VERSION ""
NS_ :

BS_:

BU_: DIM BMS DCM GSM FSM PDM DEBUG

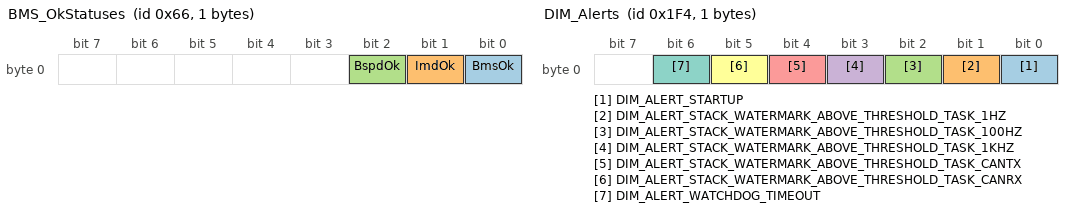
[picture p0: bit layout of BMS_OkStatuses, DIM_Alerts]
BO_ 102 BMS_OkStatuses: 1 BMS
SG_ BmsOk : 0|1@1+ (1,0) [0|1] "" DEBUG,DIM
SG_ ImdOk : 1|1@1+ (1,0) [0|1] "" DEBUG,DIM
SG_ BspdOk : 2|1@1+ (1,0) [0|1] "" DEBUG,DIM

BO_ 100 BMS_Alerts: 1 BMS
SG_ BMS_ALERT_DUMMY : 0|1@1+ (1,0) [0|1] "" DEBUG

BO_ 202 DCM_Test1: 1 DCM
SG_ Ex1 : 0|1@1+ (1,0) [0|1] "" DEBUG

BO_ 200 DCM_Alerts: 1 DCM
SG_ DCM_ALERT_DUMMY : 0|1@1+ (1,0) [0|1] "" DEBUG

BO_ 502 DIM_Vitals: 1 DIM
SG_ Heartbeat : 0|1@1+ (1,0) [0|1] "" DEBUG
SG_ State : 1|1@1+ (1,0) [0|0] "" DEBUG

BO_ 503 DIM_Switches: 1 DIM
SG_ StartSwitch : 0|1@1+ (1,0) [0|1] "" DEBUG
SG_ AuxSwitch : 1|1@1+ (1,0) [0|1] "" DEBUG

BO_ 504 DIM_Errors: 2 DIM
SG_ TxOverflowCount : 0|8@1+ (1,0) [0|255] "" DEBUG
SG_ RxOverflowCount : 8|8@1+ (1,0) [0|255] "" DEBUG

BO_ 504 DIMVitals: 1 DIM
SG_ Heartbeat : 0|1@1+ (1,0) [0|1] "" DEBUG,BMS

BO_ 500 DIM_AlertSet: 0 DIM
SG_ DIM_AlertSet : 0|0@1+ (1,0) [0|0] "" DEBUG

BO_ 500 DIM_Alerts: 1 DIM
SG_ DIM_ALERT_STARTUP : 0|1@1+ (1,0) [0|1] "" DEBUG
SG_ DIM_ALERT_STACK_WATERMARK_ABOVE_THRESHOLD_TASK_1HZ : 1|1@1+ (1,0) [0|1] "" DEBUG
SG_ DIM_ALERT_STACK_WATERMARK_ABOVE_THRESHOLD_TASK_100HZ : 2|1@1+ (1,0) [0|1] "" DEBUG
SG_ DIM_ALERT_STACK_WATERMARK_ABOVE_THRESHOLD_TASK_1KHZ : 3|1@1+ (1,0) [0|1] "" DEBUG
SG_ DIM_ALERT_STACK_WATERMARK_ABOVE_THRESHOLD_TASK_CANTX : 4|1@1+ (1,0) [0|1] "" DEBUG
SG_ DIM_ALERT_STACK_WATERMARK_ABOVE_THRESHOLD_TASK_CANRX : 5|1@1+ (1,0) [0|1] "" DEBUG
SG_ DIM_ALERT_WATCHDOG_TIMEOUT : 6|1@1+ (1,0) [0|1] "" DEBUG

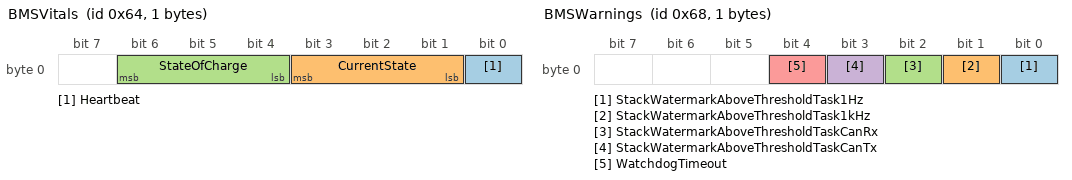
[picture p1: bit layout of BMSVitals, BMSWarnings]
BO_ 100 BMSVitals: 1 BMS
SG_ Heartbeat : 0|1@1+ (1,0) [0|1] "" DEBUG
SG_ CurrentState : 1|3@1+ (1,0) [0|4] "" DEBUG
SG_ StateOfCharge : 4|3@1+ (14.285714285714286,0) [0|100] "" DEBUG

BO_ 101 BMSCanFifoOverflow: 8 BMS
SG_ TxOverflowCount : 0|32@1+ (1,0) [0|4294967295] "" DEBUG
SG_ RxOverflowCount : 32|32@1+ (1,0) [0|4294967295] "" DEBUG

BO_ 103 BMSWatchdogTimeout: 1 BMS
SG_ TaskName : 0|3@1+ (1,0) [0|4] "" DEBUG

BO_ 104 BMSWarnings: 1 BMS
SG_ StackWatermarkAboveThresholdTask1Hz : 0|1@1+ (1,0) [0|1] "" DEBUG
SG_ StackWatermarkAboveThresholdTask1kHz : 1|1@1+ (1,0) [0|1] "" DEBUG
SG_ StackWatermarkAboveThresholdTaskCanRx : 2|1@1+ (1,0) [0|1] "" DEBUG
SG_ StackWatermarkAboveThresholdTaskCanTx : 3|1@1+ (1,0) [0|1] "" DEBUG
SG_ WatchdogTimeout : 4|1@1+ (1,0) [0|1] "" DEBUG

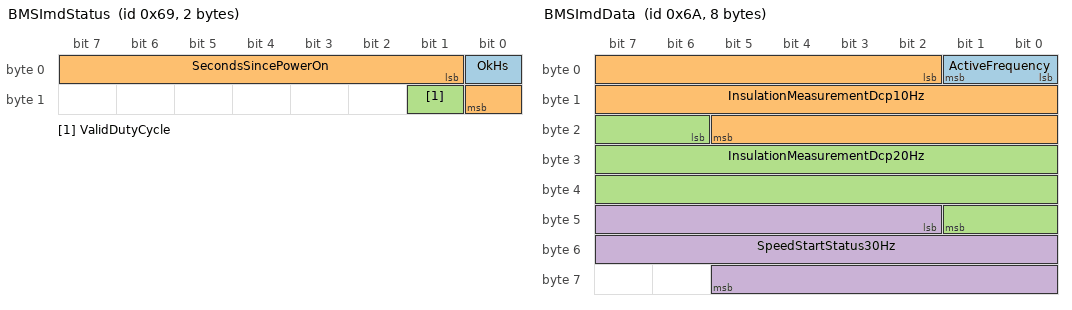
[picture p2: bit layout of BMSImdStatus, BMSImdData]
BO_ 105 BMSImdStatus: 2 BMS
SG_ OkHs : 0|1@1+ (1,0) [0|1] "" DEBUG
SG_ SecondsSincePowerOn : 1|8@1+ (1.0,0) [0|255] "Seconds" DEBUG
SG_ ValidDutyCycle : 9|1@1+ (1,0) [0|1] "" DEBUG

BO_ 106 BMSImdData: 8 BMS
SG_ ActiveFrequency : 0|2@1+ (6.666666666666667,0) [0|20] "Hz" DEBUG
SG_ InsulationMeasurementDcp10Hz : 2|20@1+ (0.1,0) [0|65535] "kOhm" DEBUG
SG_ InsulationMeasurementDcp20Hz : 22|20@1+ (0.1,0) [0|65535] "kOhm" DEBUG
SG_ SpeedStartStatus30Hz : 42|20@1+ (0.1,0) [0|65535] "" DEBUG

BO_ 107 BMSImdPwmOutput: 1 BMS
SG_ DutyCycle : 0|3@1+ (14.285714285714286,0) [0|100] "%" DEBUG
SG_ Frequency : 3|4@1+ (6.666666666666667,0) [0|100] "Hz" DEBUG

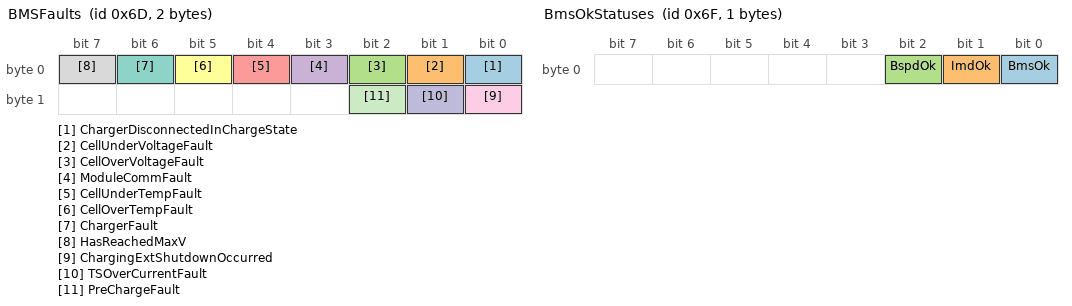
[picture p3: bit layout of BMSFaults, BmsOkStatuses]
BO_ 109 BMSFaults: 2 BMS
SG_ ChargerDisconnectedInChargeState : 0|1@1+ (1,0) [0|1] "" DEBUG
SG_ CellUnderVoltageFault : 1|1@1+ (1,0) [0|1] "" DEBUG
SG_ CellOverVoltageFault : 2|1@1+ (1,0) [0|1] "" DEBUG
SG_ ModuleCommFault : 3|1@1+ (1,0) [0|1] "" DEBUG
SG_ CellUnderTempFault : 4|1@1+ (1,0) [0|1] "" DEBUG
SG_ CellOverTempFault : 5|1@1+ (1,0) [0|1] "" DEBUG
SG_ ChargerFault : 6|1@1+ (1,0) [0|1] "" DEBUG
SG_ HasReachedMaxV : 7|1@1+ (1,0) [0|1] "" DEBUG
SG_ ChargingExtShutdownOccurred : 8|1@1+ (1,0) [0|1] "" DEBUG
SG_ TSOverCurrentFault : 9|1@1+ (1,0) [0|1] "" DEBUG
SG_ PreChargeFault : 10|1@1+ (1,0) [0|1] "" DEBUG

BO_ 110 BMSCharger: 1 BMS
SG_ IsConnected : 0|1@1+ (1,0) [0|1] "" DEBUG
SG_ IsChargingComplete : 1|1@1+ (1,0) [0|1] "" DEBUG

BO_ 111 BmsOkStatuses: 1 BMS
SG_ BmsOk : 0|1@1+ (1,0) [0|1] "" DEBUG
SG_ ImdOk : 1|1@1+ (1,0) [0|1] "" DEBUG
SG_ BspdOk : 2|1@1+ (1,0) [0|1] "" DEBUG

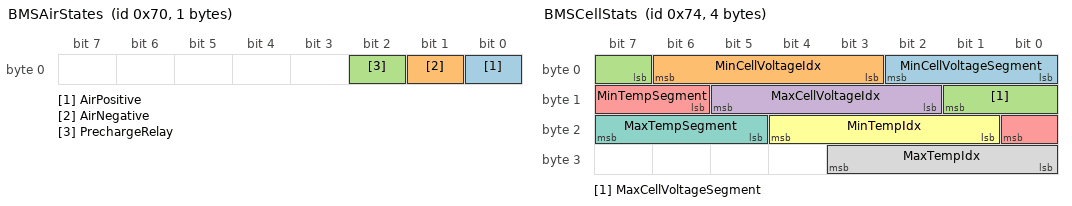
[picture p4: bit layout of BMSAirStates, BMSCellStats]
BO_ 112 BMSAirStates: 1 BMS
SG_ AirPositive : 0|1@1+ (1,0) [0|1] "" DEBUG
SG_ AirNegative : 1|1@1+ (1,0) [0|1] "" DEBUG
SG_ PrechargeRelay : 2|1@1+ (1,0) [0|1] "" DEBUG

BO_ 113 BMSMotorShutdownErrors: 1 BMS
SG_ BmsDummyMotorShutdown : 0|1@1+ (1,0) [0|1] "" DEBUG

BO_ 114 BMSCellTemperatures: 3 BMS
SG_ MinCellTemperature : 0|10@1+ (0.1,0) [0|100] "degC" DEBUG
SG_ MaxCellTemperature : 10|10@1+ (0.1,0) [0|100] "degC" DEBUG

BO_ 115 BMSCellVoltages: 4 BMS
SG_ MinCellVoltage : 0|16@1+ (0.0001,0) [0|5] "V" DEBUG
SG_ MaxCellVoltage : 16|16@1+ (0.0001,0) [0|5] "V" DEBUG

BO_ 116 BMSCellStats: 4 BMS
SG_ MinCellVoltageSegment : 0|3@1+ (1,0) [0|7] "" DEBUG
SG_ MinCellVoltageIdx : 3|4@1+ (1,0) [0|15] "" DEBUG
SG_ MaxCellVoltageSegment : 7|3@1+ (1.0,0) [0|7] "" DEBUG
SG_ MaxCellVoltageIdx : 10|4@1+ (1,0) [0|15] "" DEBUG
SG_ MinTempSegment : 14|3@1+ (1,0) [0|7] "" DEBUG
SG_ MinTempIdx : 17|4@1+ (1,0) [0|15] "" DEBUG
SG_ MaxTempSegment : 21|3@1+ (1,0) [0|7] "" DEBUG
SG_ MaxTempIdx : 24|4@1+ (1,0) [0|15] "" DEBUG

BO_ 117 BMSTractiveSystem: 5 BMS
SG_ TsVoltage : 0|23@1+ (0.0001,0) [0|600] "V" DEBUG
SG_ TsCurrent : 23|13@1+ (0.1,-300) [-300|300] "A" DEBUG

BO_ 118 BMSPackVoltage: 3 BMS
SG_ PackVoltage : 0|23@1+ (0.0001,0) [0|600] "V" DEBUG

BO_ 120 BMSAvailablePower: 3 BMS
SG_ AvailablePower : 0|20@1+ (0.1,0) [0|100000] "W" DEBUG

BO_ 150 BMS_AlertSet: 0 BMS
SG_ BMS_AlertSet : 0|0@1+ (1,0) [0|0] "" DEBUG

BO_ 151 BMS_AlertCleared: 0 BMS
SG_ BMS_AlertCleared : 0|0@1+ (1,0) [0|0] "" DEBUG

BO_ 202 DCM_Test1: 1 DCM
SG_ Ex1 : 0|1@1+ (1,0) [0|1] "" DEBUG

BO_ 203 DCMVitals: 1 DCM
SG_ Heartbeat : 0|1@1+ (1,0) [0|1] "" DEBUG,BMS

BO_ 200 DCM_AlertSet: 0 DCM
SG_ DCM_AlertSet : 0|0@1+ (1,0) [0|0] "" DEBUG

BO_ 201 DCM_AlertCleared: 0 DCM
SG_ DCM_AlertCleared : 0|0@1+ (1,0) [0|0] "" DEBUG

BO_ 603 GSM_Test1: 1 GSM
SG_ Ex1 : 0|1@1+ (1,0) [0|1] "" DEBUG

BO_ 600 GSM_Alerts: 1 GSM
SG_ GSM_ALERT_DUMMY : 0|1@1+ (1,0) [0|1] "" DEBUG

BO_ 303 FSM_Test1: 1 FSM
SG_ Ex1 : 0|1@1+ (1,0) [0|1] "" DEBUG

BO_ 304 FSMVitals: 1 FSM
SG_ Heartbeat : 0|1@1+ (1,0) [0|1] "" DEBUG,BMS

BO_ 300 FSM_AlertSet: 0 FSM
SG_ FSM_AlertSet : 0|0@1+ (1,0) [0|0] "" DEBUG

BO_ 301 FSM_AlertCleared: 0 FSM
SG_ FSM_AlertCleared : 0|0@1+ (1,0) [0|0] "" DEBUG

BO_ 403 PDM_Test1: 1 PDM
SG_ Ex1 : 0|1@1+ (1,0) [0|1] "" DEBUG

BO_ 404 PDMVitals: 1 PDM
SG_ Heartbeat : 0|1@1+ (1,0) [0|1] "" DEBUG,BMS

BO_ 400 PDM_AlertSet: 0 PDM
SG_ PDM_AlertSet : 0|0@1+ (1,0) [0|0] "" DEBUG

BO_ 401 PDM_AlertCleared: 0 PDM
SG_ PDM_AlertCleared : 0|0@1+ (1,0) [0|0] "" DEBUG

BA_DEF_  "BusType" STRING ;
BA_DEF_DEF_  "BusType" "CAN";

BA_ "GenSigStartValue" SG_ 502 Ex1 0;
BA_ "GenSigStartValue" SG_ 502 Ex2 0;
BA_ "GenSigStartValue" SG_ 503 Ex3 0;
BA_ "GenSigStartValue" SG_ 503 Ex4 0;
BA_ "GenSigStartValue" SG_ 503 Ex5 -120;
BA_ "GenSigStartValue" SG_ 504 Heartbeat 0;
BA_ "GenSigStartValue" SG_ 500 DIM_AlertSet 0;
BA_ "GenSigStartValue" SG_ 501 DIM_AlertCleared 0;
BA_ "GenSigStartValue" SG_ 100 Heartbeat 0;
BA_ "GenSigStartValue" SG_ 100 CurrentState 0;
BA_ "GenSigStartValue" SG_ 100 StateOfCharge 0;
BA_ "GenSigStartValue" SG_ 101 TxOverflowCount 0;
BA_ "GenSigStartValue" SG_ 101 RxOverflowCount 0;
BA_ "GenSigStartValue" SG_ 103 TaskName 0;
BA_ "GenSigStartValue" SG_ 104 StackWatermarkAboveThresholdTask1Hz 0;
BA_ "GenSigStartValue" SG_ 104 StackWatermarkAboveThresholdTask1kHz 0;
BA_ "GenSigStartValue" SG_ 104 StackWatermarkAboveThresholdTaskCanRx 0;
BA_ "GenSigStartValue" SG_ 104 StackWatermarkAboveThresholdTaskCanTx 0;
BA_ "GenSigStartValue" SG_ 104 WatchdogTimeout 0;
BA_ "GenSigStartValue" SG_ 105 OkHs 0;
BA_ "GenSigStartValue" SG_ 105 SecondsSincePowerOn 0;
BA_ "GenSigStartValue" SG_ 105 ValidDutyCycle 0;
BA_ "GenSigStartValue" SG_ 106 ActiveFrequency 0;
BA_ "GenSigStartValue" SG_ 106 InsulationMeasurementDcp10Hz 0;
BA_ "GenSigStartValue" SG_ 106 InsulationMeasurementDcp20Hz 0;
BA_ "GenSigStartValue" SG_ 106 SpeedStartStatus30Hz 0;
BA_ "GenSigStartValue" SG_ 107 DutyCycle 0;
BA_ "GenSigStartValue" SG_ 107 Frequency 0;
BA_ "GenSigStartValue" SG_ 109 ChargerDisconnectedInChargeState 0;
BA_ "GenSigStartValue" SG_ 109 CellUnderVoltageFault 0;
BA_ "GenSigStartValue" SG_ 109 CellOverVoltageFault 0;
BA_ "GenSigStartValue" SG_ 109 ModuleCommFault 0;
BA_ "GenSigStartValue" SG_ 109 CellUnderTempFault 0;
BA_ "GenSigStartValue" SG_ 109 CellOverTempFault 0;
BA_ "GenSigStartValue" SG_ 109 ChargerFault 0;
BA_ "GenSigStartValue" SG_ 109 HasReachedMaxV 0;
BA_ "GenSigStartValue" SG_ 109 ChargingExtShutdownOccurred 0;
BA_ "GenSigStartValue" SG_ 109 TSOverCurrentFault 0;
BA_ "GenSigStartValue" SG_ 109 PreChargeFault 0;
BA_ "GenSigStartValue" SG_ 110 IsConnected 0;
BA_ "GenSigStartValue" SG_ 110 IsChargingComplete 0;
BA_ "GenSigStartValue" SG_ 111 BmsOk 0;
BA_ "GenSigStartValue" SG_ 111 ImdOk 0;
BA_ "GenSigStartValue" SG_ 111 BspdOk 0;
BA_ "GenSigStartValue" SG_ 112 AirPositive 0;
BA_ "GenSigStartValue" SG_ 112 AirNegative 0;
BA_ "GenSigStartValue" SG_ 112 PrechargeRelay 0;
BA_ "GenSigStartValue" SG_ 113 BmsDummyMotorShutdown 0;
BA_ "GenSigStartValue" SG_ 114 MinCellTemperature 0;
BA_ "GenSigStartValue" SG_ 114 MaxCellTemperature 0;
BA_ "GenSigStartValue" SG_ 115 MinCellVoltage 0;
BA_ "GenSigStartValue" SG_ 115 MaxCellVoltage 0;
BA_ "GenSigStartValue" SG_ 116 MinCellVoltageSegment 0;
BA_ "GenSigStartValue" SG_ 116 MinCellVoltageIdx 0;
BA_ "GenSigStartValue" SG_ 116 MaxCellVoltageSegment 0;
BA_ "GenSigStartValue" SG_ 116 MaxCellVoltageIdx 0;
BA_ "GenSigStartValue" SG_ 116 MinTempSegment 0;
BA_ "GenSigStartValue" SG_ 116 MinTempIdx 0;
BA_ "GenSigStartValue" SG_ 116 MaxTempSegment 0;
BA_ "GenSigStartValue" SG_ 116 MaxTempIdx 0;
BA_ "GenSigStartValue" SG_ 117 TsVoltage 0;
BA_ "GenSigStartValue" SG_ 117 TsCurrent -300;
BA_ "GenSigStartValue" SG_ 118 PackVoltage 0;
BA_ "GenSigStartValue" SG_ 120 AvailablePower 0;
BA_ "GenSigStartValue" SG_ 150 BMS_AlertSet 0;
BA_ "GenSigStartValue" SG_ 151 BMS_AlertCleared 0;
BA_ "GenSigStartValue" SG_ 202 Ex1 0;
BA_ "GenSigStartValue" SG_ 203 Heartbeat 0;
BA_ "GenSigStartValue" SG_ 200 DCM_AlertSet 0;
BA_ "GenSigStartValue" SG_ 201 DCM_AlertCleared 0;
BA_ "GenSigStartValue" SG_ 603 Ex1 0;
BA_ "GenSigStartValue" SG_ 600 GSM_AlertSet 0;
BA_ "GenSigStartValue" SG_ 601 GSM_AlertCleared 0;
BA_ "GenSigStartValue" SG_ 303 Ex1 0;
BA_ "GenSigStartValue" SG_ 304 Heartbeat 0;
BA_ "GenSigStartValue" SG_ 300 FSM_AlertSet 0;
BA_ "GenSigStartValue" SG_ 301 FSM_AlertCleared 0;
BA_ "GenSigStartValue" SG_ 403 Ex1 0;
BA_ "GenSigStartValue" SG_ 404 Heartbeat 0;
BA_ "GenSigStartValue" SG_ 400 PDM_AlertSet 0;
BA_ "GenSigStartValue" SG_ 401 PDM_AlertCleared 0;

BA_ "GenMsgCycleTime" BO_ 502  1000;
BA_ "GenMsgCycleTime" BO_ 503  10;
BA_ "GenMsgCycleTime" BO_ 504  1000;
BA_ "GenMsgCycleTime" BO_ 100  100;
BA_ "GenMsgCycleTime" BO_ 101  5000;
BA_ "GenMsgCycleTime" BO_ 103  1000;
BA_ "GenMsgCycleTime" BO_ 104  1000;
BA_ "GenMsgCycleTime" BO_ 105  1000;
BA_ "GenMsgCycleTime" BO_ 106  1000;
BA_ "GenMsgCycleTime" BO_ 107  1000;
BA_ "GenMsgCycleTime" BO_ 109  1000;
BA_ "GenMsgCycleTime" BO_ 110  1000;
BA_ "GenMsgCycleTime" BO_ 111  10;
BA_ "GenMsgCycleTime" BO_ 112  10;
BA_ "GenMsgCycleTime" BO_ 113  1000;
BA_ "GenMsgCycleTime" BO_ 114  100;
BA_ "GenMsgCycleTime" BO_ 115  100;
BA_ "GenMsgCycleTime" BO_ 116  100;
BA_ "GenMsgCycleTime" BO_ 117  100;
BA_ "GenMsgCycleTime" BO_ 118  100;
BA_ "GenMsgCycleTime" BO_ 120  100;
BA_ "GenMsgCycleTime" BO_ 202  1000;
BA_ "GenMsgCycleTime" BO_ 203  1000;
BA_ "GenMsgCycleTime" BO_ 603  1000;
BA_ "GenMsgCycleTime" BO_ 303  1000;
BA_ "GenMsgCycleTime" BO_ 304  1000;
BA_ "GenMsgCycleTime" BO_ 403  1000;
BA_ "GenMsgCycleTime" BO_ 404  1000;

VAL_ 503 Ex4 0 "CHOICE_0" 1 "CHOICE_1" 2 "CHOICE_2";
VAL_ 500 DIM_AlertSet 0 "NUM_DIM_ALERTS";
VAL_ 501 DIM_AlertCleared 0 "NUM_DIM_ALERTS";
VAL_ 100 CurrentState 0 "BMS_INIT_STATE" 1 "BMS_PRECHARGE_STATE" 2 "BMS_CHARGE_STATE" 3 "BMS_DRIVE_STATE" 4 "BMS_FAULT_STATE";
VAL_ 103 TaskName 0 "F1HZ" 1 "F100HZ" 2 "F1KHz" 3 "CAN_RX" 4 "CAN_TX";
VAL_ 150 BMS_AlertSet 0 "NUM_BMS_ALERTS";
VAL_ 151 BMS_AlertCleared 0 "NUM_BMS_ALERTS";
VAL_ 200 DCM_AlertSet 0 "NUM_DCM_ALERTS";
VAL_ 201 DCM_AlertCleared 0 "NUM_DCM_ALERTS";
VAL_ 600 GSM_AlertSet 0 "NUM_GSM_ALERTS";
VAL_ 601 GSM_AlertCleared 0 "NUM_GSM_ALERTS";
VAL_ 300 FSM_AlertSet 0 "NUM_FSM_ALERTS";
VAL_ 301 FSM_AlertCleared 0 "NUM_FSM_ALERTS";
VAL_ 400 PDM_AlertSet 0 "NUM_PDM_ALERTS";
VAL_ 401 PDM_AlertCleared 0 "NUM_PDM_ALERTS";
